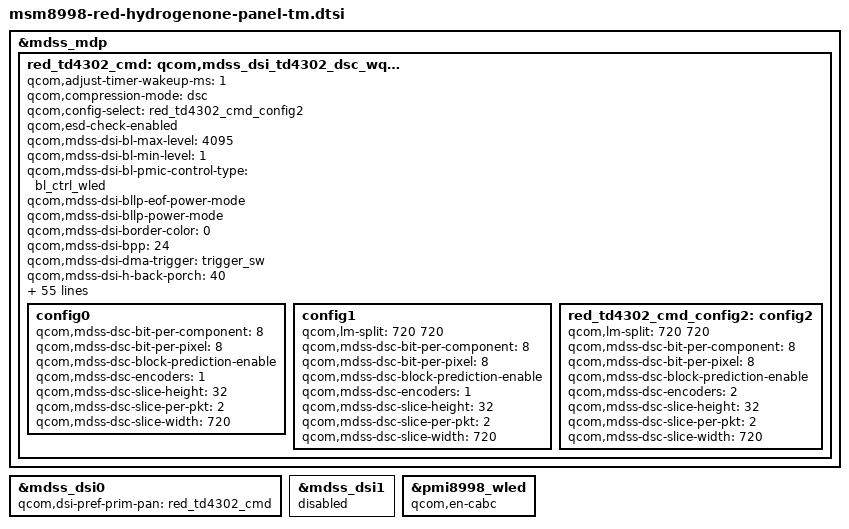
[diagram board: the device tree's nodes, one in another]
/*
 * Copyright (c) 2026, The LineageOS Project. All rights reserved.
 *
 * This program is free software; you can redistribute it and/or modify
 * it under the terms of the GNU General Public License version 2 and
 * only version 2 as published by the Free Software Foundation.
 */

/* TM display and touch properties are isolated in this layer. */

&mdss_mdp {
	red_td4302_cmd: qcom,mdss_dsi_td4302_dsc_wqhd_cmd {
		qcom,adjust-timer-wakeup-ms = <1>;
		qcom,compression-mode = "dsc";
		qcom,config-select = <&red_td4302_cmd_config2>;
		qcom,esd-check-enabled;
		qcom,mdss-dsi-bl-max-level = <4095>;
		qcom,mdss-dsi-bl-min-level = <1>;
		qcom,mdss-dsi-bl-pmic-control-type = "bl_ctrl_wled";
		qcom,mdss-dsi-bllp-eof-power-mode;
		qcom,mdss-dsi-bllp-power-mode;
		qcom,mdss-dsi-border-color = <0>;
		qcom,mdss-dsi-bpp = <24>;
		qcom,mdss-dsi-dma-trigger = "trigger_sw";
		qcom,mdss-dsi-h-back-porch = <40>;
		qcom,mdss-dsi-h-front-porch = <40>;
		qcom,mdss-dsi-h-pulse-width = <8>;
		qcom,mdss-dsi-h-sync-pulse = <0>;
		qcom,mdss-dsi-h-sync-skew = <0>;
		qcom,mdss-dsi-lane-0-state;
		qcom,mdss-dsi-lane-1-state;
		qcom,mdss-dsi-lane-2-state;
		qcom,mdss-dsi-lane-3-state;
		qcom,mdss-dsi-mdp-trigger = "none";
		qcom,mdss-dsi-off-command =
			[05 01 00 00 0a 00 02 28 00
			 05 01 00 00 0a 00 02 10 00];
		qcom,mdss-dsi-off-command-state = "dsi_hs_mode";
		qcom,mdss-dsi-on-command =
			[23 01 00 00 00 00 02 b0 04
			 29 01 00 00 00 00 04 b3 00 00 06
			 23 01 00 00 00 00 02 d6 01
			 15 01 00 00 00 00 02 35 00
			 15 01 00 00 00 00 02 51 ff
			 15 01 00 00 00 00 02 53 04
			 15 01 00 00 00 00 02 55 01
			 29 01 00 00 00 00 08 b8 57 3d 19 1e 0a 50 50
			 29 01 00 00 00 00 06 b6 31 bb 01 ff ff
			 29 01 00 00 00 00 05 c2 01 fa 00 0a
			 29 01 00 00 00 00 02 be 00
			 29 01 00 00 00 00 02 e7 80
			 29 01 00 00 00 00 03 eb 8b 8b
			 29 01 00 00 00 00 02 ec 01
			 29 01 00 00 05 00 81 e9 11 00 00 89 30 80 0a
			 00 05 a0 00 20 02 d0 02 d0 02 00 02 68 00 20
			 03 87 00 0a 00 0c 03 19 02 63 18 00 10 f0 03
			 0c 20 00 06 0b 0b 33 0e 1c 2a 38 46 54 62 69
			 70 77 79 7b 7d 7e 01 02 01 00 09 40 09 be 19
			 fc 19 fa 19 f8 1a 38 1a 78 1a b6 2a f6 2b 34
			 2b 74 3b 74 6b f4 00 00 00 00 00 00 00 00 00
			 00 00 00 00 00 00 00 00 00 00 00 00 00 00 00
			 00 00 00 00 00 00 00 00 00 00 00 00 00 00 00
			 00 05 01 00 00 00 00 01 11
			 05 01 00 00 00 00 01 29];
		qcom,mdss-dsi-on-command-state = "dsi_lp_mode";
		qcom,mdss-dsi-panel-blackness-level = <3000>;
		qcom,mdss-dsi-panel-framerate = <60>;
		qcom,mdss-dsi-panel-height = <2560>;
		qcom,mdss-dsi-panel-max-error-count = <3>;
		qcom,mdss-dsi-panel-name = "TD4302 cmd mode dsc dsi panel";
		qcom,mdss-dsi-panel-on-check-value = <0x1c>;
		qcom,mdss-dsi-panel-peak-brightness = <4500000>;
		qcom,mdss-dsi-panel-status-check-mode = "reg_read";
		qcom,mdss-dsi-panel-status-command = <0x06010001 0x0000010a>;
		qcom,mdss-dsi-panel-status-command-state = "dsi_hs_mode";
		qcom,mdss-dsi-panel-status-read-length = <1>;
		qcom,mdss-dsi-panel-status-value = <0x1c>;
		qcom,mdss-dsi-panel-timings = <0x00130504 0x1f1e0505 0x03030400>;
		qcom,mdss-dsi-panel-type = "dsi_cmd_mode";
		qcom,mdss-dsi-panel-width = <1440>;
		qcom,mdss-dsi-reset-sequence = <0 10 1 5>;
		qcom,mdss-dsi-stream = <0>;
		qcom,mdss-dsi-t-clk-post = <0x0b>;
		qcom,mdss-dsi-t-clk-pre = <0x24>;
		qcom,mdss-dsi-te-check-enable;
		qcom,mdss-dsi-te-dcs-command = <1>;
		qcom,mdss-dsi-te-pin-select = <1>;
		qcom,mdss-dsi-te-using-te-pin;
		qcom,mdss-dsi-traffic-mode = "non_burst_sync_event";
		qcom,mdss-dsi-tx-eot-append;
		qcom,mdss-dsi-v-back-porch = <7>;
		qcom,mdss-dsi-v-front-porch = <8>;
		qcom,mdss-dsi-v-pulse-width = <1>;
		qcom,mdss-dsi-virtual-channel-id = <0>;
		qcom,mdss-pan-physical-height-dimension = <126>;
		qcom,mdss-pan-physical-width-dimension = <71>;
		qcom,panel-supply-entries = <&dsi_panel_pwr_supply>;
		qcom,ulps-enabled;

		config0 {
			qcom,mdss-dsc-bit-per-component = <8>;
			qcom,mdss-dsc-bit-per-pixel = <8>;
			qcom,mdss-dsc-block-prediction-enable;
			qcom,mdss-dsc-encoders = <1>;
			qcom,mdss-dsc-slice-height = <32>;
			qcom,mdss-dsc-slice-per-pkt = <2>;
			qcom,mdss-dsc-slice-width = <720>;
		};

		config1 {
			qcom,lm-split = <720 720>;
			qcom,mdss-dsc-bit-per-component = <8>;
			qcom,mdss-dsc-bit-per-pixel = <8>;
			qcom,mdss-dsc-block-prediction-enable;
			qcom,mdss-dsc-encoders = <1>;
			qcom,mdss-dsc-slice-height = <32>;
			qcom,mdss-dsc-slice-per-pkt = <2>;
			qcom,mdss-dsc-slice-width = <720>;
		};

		red_td4302_cmd_config2: config2 {
			qcom,lm-split = <720 720>;
			qcom,mdss-dsc-bit-per-component = <8>;
			qcom,mdss-dsc-bit-per-pixel = <8>;
			qcom,mdss-dsc-block-prediction-enable;
			qcom,mdss-dsc-encoders = <2>;
			qcom,mdss-dsc-slice-height = <32>;
			qcom,mdss-dsc-slice-per-pkt = <2>;
			qcom,mdss-dsc-slice-width = <720>;
		};
	};
};

&mdss_dsi0 {
	qcom,dsi-pref-prim-pan = <&red_td4302_cmd>;
	/delete-property/ qcom,panel-mode-gpio;
};

&mdss_dsi1 {
	status = "disabled";
};

&pmi8998_wled {
	qcom,en-cabc;
};
